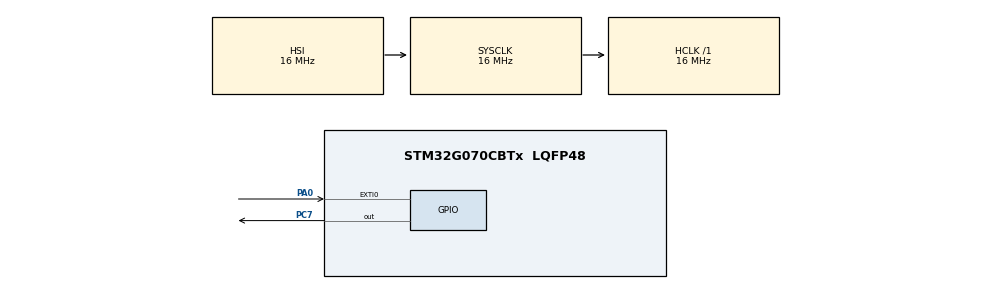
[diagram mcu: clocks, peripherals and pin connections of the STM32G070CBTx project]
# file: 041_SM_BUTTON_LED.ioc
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Mcu.Family=STM32G0
Mcu.Name=STM32G070CBTx
Mcu.Package=LQFP48
NVIC.EXTI0_1_IRQn=true\:0\:0\:false\:false\:true\:true\:true\:true
PA0.GPIO_PuPd=GPIO_PULLDOWN
PA0.Signal=GPXTI0
PC7.GPIO_ModeDefaultOutputPP=GPIO_MODE_OUTPUT_OD
PC7.GPIO_PuPd=GPIO_NOPULL
PC7.Signal=GPIO_Output
ProjectManager.HeapSize=0x200
ProjectManager.StackSize=0x400
ProjectManager.TargetToolchain=STM32CubeIDE
RCC.AHBFreq_Value=16000000
RCC.CortexFreq_Value=16000000
RCC.EXTERNAL_CLOCK_VALUE=48000
RCC.HCLKFreq_Value=16000000
RCC.HSE_VALUE=8000000
RCC.HSI_VALUE=16000000
RCC.LSE_VALUE=32768
RCC.SYSCLKFreq_VALUE=16000000
RCC.VCOOutputFreq_Value=128000000
board=custom

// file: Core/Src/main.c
/* USER CODE BEGIN Header */
/**
  ******************************************************************************
  * @file           : main.c
  * @brief          : Main program body
  ******************************************************************************
  * @attention
  *
  * Copyright (c) 2023 STMicroelectronics.
  * All rights reserved.
  *
  * This software is licensed under terms that can be found in the LICENSE file
  * in the root directory of this software component.
  * If no LICENSE file comes with this software, it is provided AS-IS.
  *
  ******************************************************************************
  */
/* USER CODE END Header */
#include "main.h"

/* USER CODE BEGIN PTD */
typedef enum{

	SM_Error,
	SM_Idle,
	SM_LedOn,
	SM_LedOff,
	SM_Delay

}SM_LED_State;

SM_LED_State SM_LED_state;
SM_LED_State SM_LED_next_state;
/* USER CODE END PTD */

void SystemClock_Config(void);
static void MX_GPIO_Init(void);

/* USER CODE BEGIN 0 */
void EXTI0_IRQHandler(void)
{
	SM_LED_state = SM_LedOn;
}
/* USER CODE END 0 */

int main(void)
{

  /* MCU Configuration--------------------------------------------------------*/

  /* Reset of all peripherals, Initializes the Flash interface and the Systick. */
  HAL_Init();

  /* Configure the system clock */
  SystemClock_Config();

  /* Initialize all configured peripherals */
  MX_GPIO_Init();
  /* USER CODE BEGIN 2 */
  SM_LED_state = SM_Idle;
  /* USER CODE END 2 */

  /* Infinite loop */
  while (1)
  {

  }
}

void SystemClock_Config(void)
{
  RCC_OscInitTypeDef RCC_OscInitStruct = {0};
  RCC_ClkInitTypeDef RCC_ClkInitStruct = {0};

  /** Configure the main internal regulator output voltage
  */
  HAL_PWREx_ControlVoltageScaling(PWR_REGULATOR_VOLTAGE_SCALE1);

  /** Initializes the RCC Oscillators according to the specified parameters
  * in the RCC_OscInitTypeDef structure.
  */
  RCC_OscInitStruct.OscillatorType = RCC_OSCILLATORTYPE_HSI;
  RCC_OscInitStruct.HSIState = RCC_HSI_ON;
  RCC_OscInitStruct.HSIDiv = RCC_HSI_DIV1;
  RCC_OscInitStruct.HSICalibrationValue = RCC_HSICALIBRATION_DEFAULT;
  RCC_OscInitStruct.PLL.PLLState = RCC_PLL_NONE;
  if (HAL_RCC_OscConfig(&RCC_OscInitStruct) != HAL_OK)
  {
    Error_Handler();
  }

  /** Initializes the CPU, AHB and APB buses clocks
  */
  RCC_ClkInitStruct.ClockType = RCC_CLOCKTYPE_HCLK|RCC_CLOCKTYPE_SYSCLK
                              |RCC_CLOCKTYPE_PCLK1;
  RCC_ClkInitStruct.SYSCLKSource = RCC_SYSCLKSOURCE_HSI;
  RCC_ClkInitStruct.AHBCLKDivider = RCC_SYSCLK_DIV1;
  RCC_ClkInitStruct.APB1CLKDivider = RCC_HCLK_DIV1;

  if (HAL_RCC_ClockConfig(&RCC_ClkInitStruct, FLASH_LATENCY_0) != HAL_OK)
  {
    Error_Handler();
  }
}

static void MX_GPIO_Init(void)
{
  GPIO_InitTypeDef GPIO_InitStruct = {0};

  /* GPIO Ports Clock Enable */
  __HAL_RCC_GPIOA_CLK_ENABLE();
  __HAL_RCC_GPIOC_CLK_ENABLE();

  /*Configure GPIO pin Output Level */
  HAL_GPIO_WritePin(GPIOC, GPIO_PIN_7, GPIO_PIN_RESET);

  /*Configure GPIO pin : PA0 */
  GPIO_InitStruct.Pin = GPIO_PIN_0;
  GPIO_InitStruct.Mode = GPIO_MODE_IT_RISING;
  GPIO_InitStruct.Pull = GPIO_PULLDOWN;
  HAL_GPIO_Init(GPIOA, &GPIO_InitStruct);

  /*Configure GPIO pin : PC7 */
  GPIO_InitStruct.Pin = GPIO_PIN_7;
  GPIO_InitStruct.Mode = GPIO_MODE_OUTPUT_OD;
  GPIO_InitStruct.Pull = GPIO_NOPULL;
  GPIO_InitStruct.Speed = GPIO_SPEED_FREQ_LOW;
  HAL_GPIO_Init(GPIOC, &GPIO_InitStruct);

  /* EXTI interrupt init*/
  HAL_NVIC_SetPriority(EXTI0_1_IRQn, 0, 0);
  HAL_NVIC_EnableIRQ(EXTI0_1_IRQn);

}

void Error_Handler(void)
{
  /* USER CODE BEGIN Error_Handler_Debug */
  /* User can add his own implementation to report the HAL error return state */
  __disable_irq();
  while (1)
  {
	  switch(SM_LED_state)
	  {
	  	case SM_Error:
	  	{
	  		break;
	  	}
	  	case SM_Idle:
	  	{
	  		break;
	  	}
	  	case SM_LedOn:
	  	{
	  		HAL_GPIO_WritePin(GPIOC, GPIO_PIN_7, GPIO_PIN_RESET);
	  		SM_LED_state = SM_Delay;
	  		SM_LED_next_state = SM_LedOff;
	  		break;
	  	}
	  	case SM_LedOff:
	  	{
	  		HAL_GPIO_WritePin(GPIOC, GPIO_PIN_7, GPIO_PIN_SET);
	  		SM_LED_state = SM_Delay;
	  		SM_LED_next_state = SM_Idle;
	  		break;
	  	}
	  	case SM_Delay:
	  	{
	  		HAL_Delay(1000);
	  		break;
	  	}
	  	default:
	  	{
	  		SM_LED_state = SM_Error;
	  		break;
	  	}

	  }
  }
  /* USER CODE END Error_Handler_Debug */
}
